# STM32WBA20xx register map
File version: 1.0
Registers are 32-bit, read-write, reset 0x0 unless marked. A register's access mark holds for its fields unless they carry their own. Offsets are from the block's base; [hi:lo] are bit positions; {n}, {i} and the like mark numbered series.

## EXTI — Asynch Interrupt/Event Controller (EXTI)
Base 0x46022000
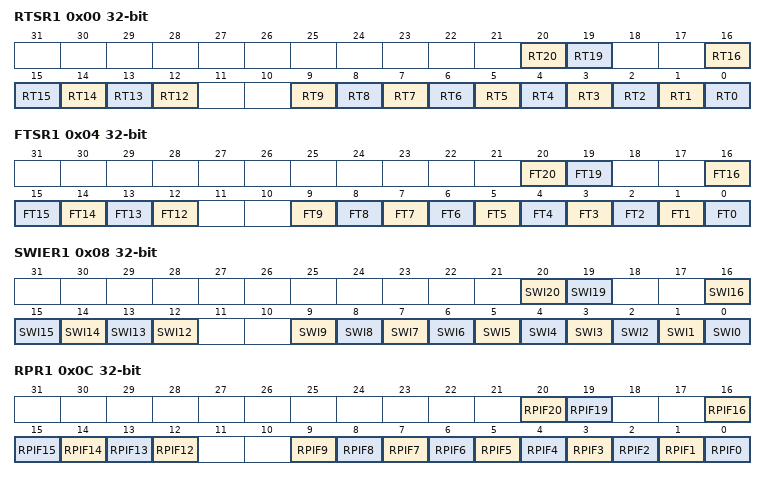
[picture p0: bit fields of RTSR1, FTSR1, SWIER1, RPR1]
0x00 RTSR1 — EXTI Rising Trigger Selection Register 1
  [20] RT20 — RT20 (Rising trigger event configuration bit of configurable event input x<sup>(1)</sup>)
  [19] RT19 — RT19 (Rising trigger event configuration bit of configurable event input x<sup>(1)</sup>)
  [n] RT{n} (n=12..16) — Rising trigger configuration for input line {n}
  [n] RT{n} (n=0..9) — Rising trigger configuration for input line {n}
0x04 FTSR1 — EXTI Falling Trigger Selection Register 1
  [20] FT20 — FT20 (Falling trigger event configuration bit of configurable event input x<sup>(1)</sup>)
  [19] FT19 — FT19 (Falling trigger event configuration bit of configurable event input x<sup>(1)</sup>)
  [n] FT{n} (n=12..16) — Falling trigger configuration for input line {n}
  [n] FT{n} (n=0..9) — Falling trigger configuration for input line {n}
0x08 SWIER1 — EXTI Software Interrupt event Register 1
  [20] SWI20 — SWI20 (Software interrupt on event x)
  [19] SWI19 — SWI19 (Software interrupt on event x)
  [n] SWI{n} (n=12..16) — Software Interrupt on line {n}
  [n] SWI{n} (n=0..9) — Software Interrupt on line {n}
0x0C RPR1 — EXTI Rising Pending Register 1
  [20] RPIF20 — RPIF20 (configurable event inputs x rising edge pending bit)
  [19] RPIF19 — RPIF19 (configurable event inputs x rising edge pending bit)
  [n] RPIF{n} (n=12..16) — Rising Pending Interrupt Flag on line {n}
  [n] RPIF{n} (n=0..9) — Rising Pending Interrupt Flag on line {n}
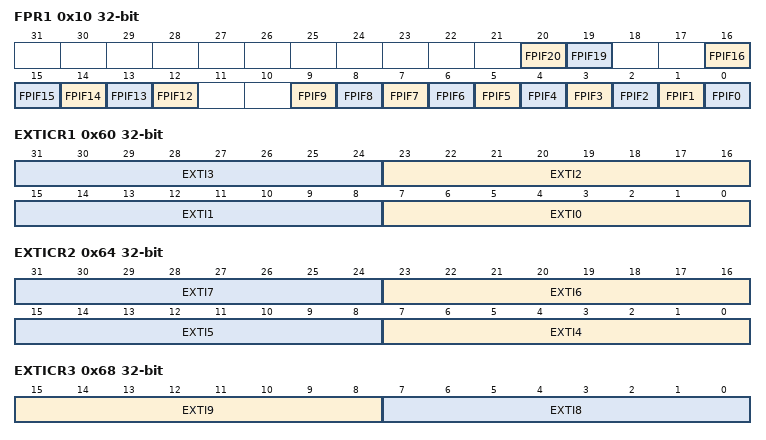
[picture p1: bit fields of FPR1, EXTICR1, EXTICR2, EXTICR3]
0x10 FPR1 — EXTI Falling Pending Register 1
  [20] FPIF20 — FPIF20 (configurable event inputs x falling edge pending bit)
  [19] FPIF19 — FPIF19 (configurable event inputs x falling edge pending bit)
  [n] FPIF{n} (n=12..16) — Falling Pending Interrupt Flag on line {n}
  [n] FPIF{n} (n=0..9) — Falling Pending Interrupt Flag on line {n}
0x60 EXTICR1 — EXIT External Interrupt Configuration Register, 0x60 -- 0x6C
  [8n+7:8n] EXTI{n} (n=0..3) — EXTI {n} configuration
0x64 EXTICR2 — EXIT External Interrupt Configuration Register, 0x60 -- 0x6C
  [8n-25:8n-32] EXTI{n} (n=4..7) — EXTI {n} configuration
0x68 EXTICR3 — EXIT External Interrupt Configuration Register, 0x60 -- 0x6C
  [15:8] EXTI9 — EXTI 9 configuration
  [7:0] EXTI8 — EXTI 8 configuration
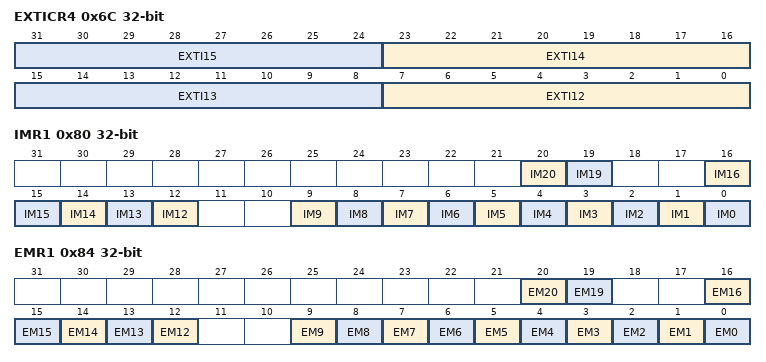
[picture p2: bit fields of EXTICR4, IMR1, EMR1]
0x6C EXTICR4 — EXIT External Interrupt Configuration Register, 0x60 -- 0x6C
  [8n-89:8n-96] EXTI{n} (n=12..15) — EXTI {n} configuration
0x80 IMR1 — EXTI Interrupt Mask Register 1
  [20] IM20 — IM20 (CPU wakeup with interrupt mask on event input x<sup>(1)</sup>)
  [19] IM19 — IM19 (CPU wakeup with interrupt mask on event input x<sup>(1)</sup>)
  [n] IM{n} (n=12..16) — Interrupt Mask on line {n}
  [n] IM{n} (n=0..9) — Interrupt Mask on line {n}
0x84 EMR1 — EXTI Event Mask Register 1
  [20] EM20 — EM20 (CPU wakeup with event generation mask on event input x)
  [19] EM19 — EM19 (CPU wakeup with event generation mask on event input x)
  [n] EM{n} (n=12..16) — Event Mask on line {n}
  [n] EM{n} (n=0..9) — Event Mask on line {n}

## DBGMCU — Debug MCU
Base 0xE0044000
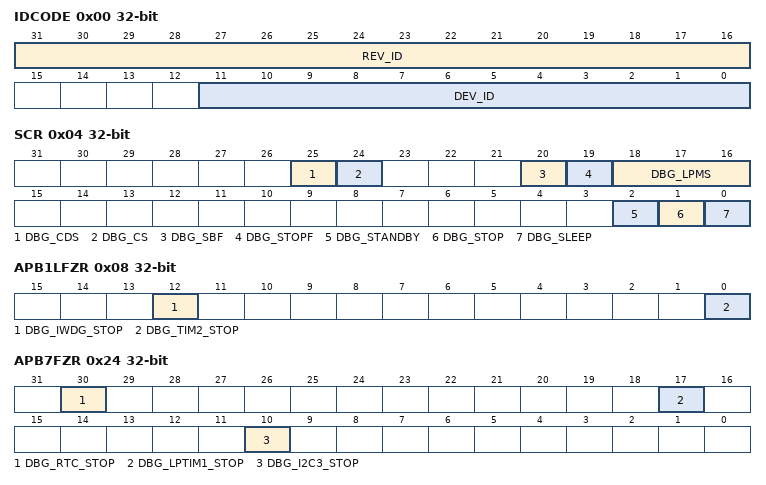
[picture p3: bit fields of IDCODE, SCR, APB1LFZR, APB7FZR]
0x00 IDCODE — MCU device ID code
  [31:16] REV_ID, [11:0] DEV_ID
0x04 SCR — Debug MCU status and configuration register
  [25] DBG_CDS
  [24] DBG_CS
  [20] DBG_SBF
  [19] DBG_STOPF
  [18:16] DBG_LPMS
  [2] DBG_STANDBY
  [1] DBG_STOP
  [0] DBG_SLEEP — DBG_SLEEP (Allows SRAM access in Sleep mode)
0x08 APB1LFZR — Debug MCU APB1 freeze register 1
  [12] DBG_IWDG_STOP, [0] DBG_TIM2_STOP
0x0C APB1HFZR — Debug MCU APB1 freeze register 2
0x10 APB2FZR — Debug MCU APB2 freeze register
  [17] DBG_TIM16_STOP
0x24 APB7FZR — Debug MCU APB7 freeze register
  [30] DBG_RTC_STOP, [17] DBG_LPTIM1_STOP, [10] DBG_I2C3_STOP
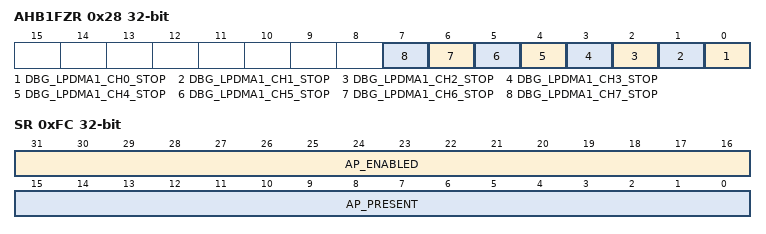
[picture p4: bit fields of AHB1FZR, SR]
0x28 AHB1FZR — Debug MCU AHB1 freeze register
  [n] DBG_LPDMA1_CH{n}_STOP (n=0..7) — DBG_LPDMA1_CH{n}_STOP (LPDMA 1 channel {n} stop in CPU debug)
0xFC SR — Debug MCU status register
  [31:16] AP_ENABLED — AP_ENABLED[15:0] bits (Bit n identifies whether access port APn is open (can be accessed via the debug port) or locked (debug access to the APn is blocked, except for DBGMCU access))
  [15:0] AP_PRESENT — AP_PRESENT[15:0] bits (Bit n identifies whether access port APn is present in device)
0x100 DBG_AUTH_HOST — Debug MCU debug host authentication register
  [31:0] AUTH_KEY — AUTH_KEY[31:0] bits (Device authentication key)
0x104 DBG_AUTH_DEVICE — Debug MCU debug device authentication register
  [31:0] AUTH_ID — AUTH_ID[31:0] bits (Device specific ID)
